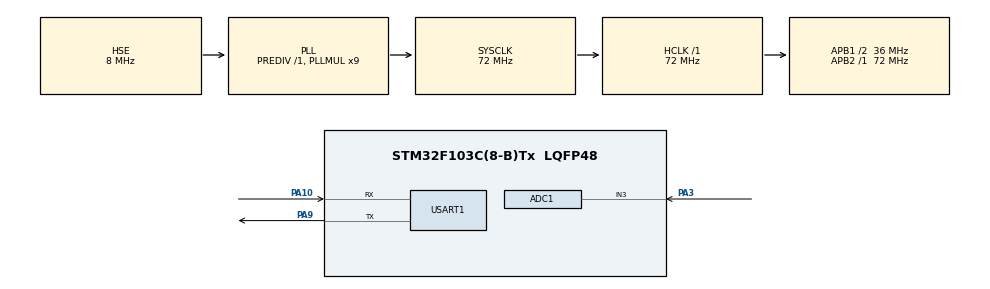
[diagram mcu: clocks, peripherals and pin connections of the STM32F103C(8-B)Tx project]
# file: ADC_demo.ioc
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ADC1.Channel-2\#ChannelRegularConversion=ADC_CHANNEL_3
ADC1.Channel-3\#ChannelInjectedConversion=ADC_CHANNEL_3
ADC1.EnableInjectedConversion=ENABLE
ADC1.InjNumberOfConversion=1
ADC1.InjectedOffset-3\#ChannelInjectedConversion=0
ADC1.InjectedRank-3\#ChannelInjectedConversion=1
ADC1.NbrOfConversionFlag=1
ADC1.Rank-2\#ChannelRegularConversion=1
ADC1.SamplingTime-2\#ChannelRegularConversion=ADC_SAMPLETIME_1CYCLE_5
ADC1.SamplingTime-3\#ChannelInjectedConversion=ADC_SAMPLETIME_1CYCLE_5
ADC1.master=1
Mcu.Family=STM32F1
Mcu.Name=STM32F103C(8-B)Tx
Mcu.Package=LQFP48
NVIC.PriorityGroup=NVIC_PRIORITYGROUP_4
PA10.Mode=Asynchronous
PA10.Signal=USART1_RX
PA13.Mode=Serial_Wire
PA13.Signal=SYS_JTMS-SWDIO
PA14.Mode=Serial_Wire
PA14.Signal=SYS_JTCK-SWCLK
PA3.Signal=ADCx_IN3
PA9.Mode=Asynchronous
PA9.Signal=USART1_TX
PD0-OSC_IN.Mode=HSE-External-Oscillator
PD0-OSC_IN.Signal=RCC_OSC_IN
PD1-OSC_OUT.Mode=HSE-External-Oscillator
PD1-OSC_OUT.Signal=RCC_OSC_OUT
ProjectManager.HeapSize=0x200
ProjectManager.StackSize=0x400
ProjectManager.TargetToolchain=MDK-ARM V5.32
RCC.ADCPresc=RCC_ADCPCLK2_DIV6
RCC.AHBFreq_Value=72000000
RCC.APB1CLKDivider=RCC_HCLK_DIV2
RCC.APB1Freq_Value=36000000
RCC.APB1TimFreq_Value=72000000
RCC.APB2Freq_Value=72000000
RCC.APB2TimFreq_Value=72000000
RCC.HCLKFreq_Value=72000000
RCC.PLLMUL=RCC_PLL_MUL9
RCC.PLLSourceVirtual=RCC_PLLSOURCE_HSE
RCC.SYSCLKFreq_VALUE=72000000
RCC.SYSCLKSource=RCC_SYSCLKSOURCE_PLLCLK
RCC.USBFreq_Value=72000000
SH.ADCx_IN3.0=ADC1_IN3,IN3
USART1.VirtualMode=VM_ASYNC
board=custom

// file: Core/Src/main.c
/* USER CODE BEGIN Header */
/*
  ******************************************************************************
	CSDN：https://blog.csdn.net/as480133937/article/details/99627062 conduct demo project
	author：Peng Shaolei
	******************************************************************************
  */
/* USER CODE END Header */
#include "main.h"
#include "adc.h"
#include "usart.h"
#include "gpio.h"

/* USER CODE BEGIN Includes */
#include <string.h>
#include <stdio.h>
/* USER CODE END Includes */

void SystemClock_Config(void);
/* USER CODE BEGIN PFP */
void UART_SendString(UART_HandleTypeDef *huart, const char* str);
void UART_SendFloat(UART_HandleTypeDef *huart, float value, int precision);
/* USER CODE END PFP */

/* USER CODE BEGIN 0 */
	uint16_t ADC_Value;  //store the value of adc
	const int ADC_Parameter = 4096;
	float Voltage = 0.0f;
	char Judgement[] = "This is a test!";
	char ADC_information[] = "ADC_Value = ";
  char attempt[] = "git is sb";
/* USER CODE END 0 */

int main(void)
{

  /* MCU Configuration--------------------------------------------------------*/

  /* Reset of all peripherals, Initializes the Flash interface and the Systick. */
  HAL_Init();

  /* Configure the system clock */
  SystemClock_Config();

  /* Initialize all configured peripherals */
  MX_GPIO_Init();
  MX_ADC1_Init();
  MX_USART1_UART_Init();
  /* USER CODE BEGIN 2 */
	HAL_ADCEx_Calibration_Start(&hadc1);  //AD Calibration

	UART_SendString(&huart1,Judgement);
  UART_SendString(&huart1,attempt);
  /* USER CODE END 2 */

  /* Infinite loop */
  while (1)
  {
		HAL_ADC_Start(&hadc1);
		HAL_ADC_PollForConversion(&hadc1,50);   // timeout = 50
		UART_SendString(&huart1,ADC_information);
		if(HAL_IS_BIT_SET(HAL_ADC_GetState(&hadc1),HAL_ADC_STATE_REG_EOC))
		{
			ADC_Value = HAL_ADC_GetValue(&hadc1);
			Voltage = ADC_Value*3.3f / ADC_Parameter; //calculate the Voltage
			/*Pay attention to the real-time update of the data!!!!! such as Voltage Don't ask me the reason!*/
			UART_SendString(&huart1,"PA3 True Voltage Value :");
			UART_SendFloat(&huart1, Voltage, 3);
			UART_SendString(&huart1, "\r\n");
			UART_SendString(&huart1,"Sun_Flower's demo%d \r\n");
		}
		HAL_Delay(100);
  }
}

void SystemClock_Config(void)
{
  RCC_OscInitTypeDef RCC_OscInitStruct = {0};
  RCC_ClkInitTypeDef RCC_ClkInitStruct = {0};
  RCC_PeriphCLKInitTypeDef PeriphClkInit = {0};

  /** Initializes the RCC Oscillators according to the specified parameters
  * in the RCC_OscInitTypeDef structure.
  */
  RCC_OscInitStruct.OscillatorType = RCC_OSCILLATORTYPE_HSE;
  RCC_OscInitStruct.HSEState = RCC_HSE_ON;
  RCC_OscInitStruct.HSEPredivValue = RCC_HSE_PREDIV_DIV1;
  RCC_OscInitStruct.HSIState = RCC_HSI_ON;
  RCC_OscInitStruct.PLL.PLLState = RCC_PLL_ON;
  RCC_OscInitStruct.PLL.PLLSource = RCC_PLLSOURCE_HSE;
  RCC_OscInitStruct.PLL.PLLMUL = RCC_PLL_MUL9;
  if (HAL_RCC_OscConfig(&RCC_OscInitStruct) != HAL_OK)
  {
    Error_Handler();
  }

  /** Initializes the CPU, AHB and APB buses clocks
  */
  RCC_ClkInitStruct.ClockType = RCC_CLOCKTYPE_HCLK|RCC_CLOCKTYPE_SYSCLK
                              |RCC_CLOCKTYPE_PCLK1|RCC_CLOCKTYPE_PCLK2;
  RCC_ClkInitStruct.SYSCLKSource = RCC_SYSCLKSOURCE_PLLCLK;
  RCC_ClkInitStruct.AHBCLKDivider = RCC_SYSCLK_DIV1;
  RCC_ClkInitStruct.APB1CLKDivider = RCC_HCLK_DIV2;
  RCC_ClkInitStruct.APB2CLKDivider = RCC_HCLK_DIV1;

  if (HAL_RCC_ClockConfig(&RCC_ClkInitStruct, FLASH_LATENCY_2) != HAL_OK)
  {
    Error_Handler();
  }
  PeriphClkInit.PeriphClockSelection = RCC_PERIPHCLK_ADC;
  PeriphClkInit.AdcClockSelection = RCC_ADCPCLK2_DIV6;
  if (HAL_RCCEx_PeriphCLKConfig(&PeriphClkInit) != HAL_OK)
  {
    Error_Handler();
  }
}

/* USER CODE BEGIN 4 */
void UART_SendString(UART_HandleTypeDef *huart, const char* str){
	HAL_UART_Transmit(huart, (uint8_t*)str, strlen(str), 50);
}

void UART_SendFloat(UART_HandleTypeDef *huart, float value, int precision) {
    char buffer[50];
    snprintf(buffer, sizeof(buffer), "%.*f", precision, value);
    HAL_UART_Transmit(huart, (uint8_t*)buffer, strlen(buffer), 50);
}

/* USER CODE END 4 */

void Error_Handler(void)
{
  __disable_irq();
  while (1)
  {
  }
}
